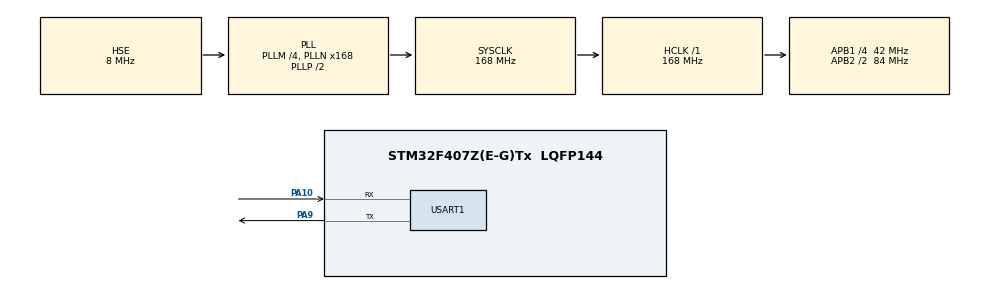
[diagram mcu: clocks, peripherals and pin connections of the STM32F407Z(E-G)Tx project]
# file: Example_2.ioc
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FREERTOS.Events01=xEventGroup,Dynamic,NULL
FREERTOS.Tasks01=Task_Syncing,24,128,AppTask_Syncing,Default,NULL,Dynamic,NULL,NULL
FREERTOS.configTICK_RATE_HZ=1000
FREERTOS.configUSE_IDLE_HOOK=0
Mcu.Family=STM32F4
Mcu.Name=STM32F407Z(E-G)Tx
Mcu.Package=LQFP144
NVIC.PriorityGroup=NVIC_PRIORITYGROUP_4
NVIC.TIM6_DAC_IRQn=true\:0\:0\:true\:false\:true\:false\:false\:true\:true
NVIC.TimeBase=TIM6_DAC_IRQn
NVIC.TimeBaseIP=TIM6
PA10.Mode=Asynchronous
PA10.Signal=USART1_RX
PA13.Mode=Serial_Wire
PA13.Signal=SYS_JTMS-SWDIO
PA14.Mode=Serial_Wire
PA14.Signal=SYS_JTCK-SWCLK
PA9.Mode=Asynchronous
PA9.Signal=USART1_TX
PC14-OSC32_IN.Mode=LSE-External-Oscillator
PC14-OSC32_IN.Signal=RCC_OSC32_IN
PC15-OSC32_OUT.Mode=LSE-External-Oscillator
PC15-OSC32_OUT.Signal=RCC_OSC32_OUT
PH0-OSC_IN.Mode=HSE-External-Oscillator
PH0-OSC_IN.Signal=RCC_OSC_IN
PH1-OSC_OUT.Mode=HSE-External-Oscillator
PH1-OSC_OUT.Signal=RCC_OSC_OUT
ProjectManager.HeapSize=0x200
ProjectManager.StackSize=0x400
ProjectManager.TargetToolchain=MDK-ARM V5.32
RCC.48MHZClocksFreq_Value=84000000
RCC.AHBFreq_Value=168000000
RCC.APB1CLKDivider=RCC_HCLK_DIV4
RCC.APB1Freq_Value=42000000
RCC.APB1TimFreq_Value=84000000
RCC.APB2CLKDivider=RCC_HCLK_DIV2
RCC.APB2Freq_Value=84000000
RCC.APB2TimFreq_Value=168000000
RCC.CortexFreq_Value=168000000
RCC.HCLKFreq_Value=168000000
RCC.HSE_VALUE=8000000
RCC.HSI_VALUE=16000000
RCC.PLLM=4
RCC.PLLN=168
RCC.PLLSourceVirtual=RCC_PLLSOURCE_HSE
RCC.RCC_RTC_Clock_Source=RCC_RTCCLKSOURCE_LSE
RCC.RCC_RTC_Clock_SourceVirtual=RCC_RTCCLKSOURCE_LSE
RCC.SYSCLKFreq_VALUE=168000000
RCC.SYSCLKSource=RCC_SYSCLKSOURCE_PLLCLK
RCC.VCOOutputFreq_Value=336000000
USART1.VirtualMode=VM_ASYNC
VP_FREERTOS_VS_CMSIS_V2.Mode=CMSIS_V2
VP_SYS_VS_tim6.Mode=TIM6
board=custom

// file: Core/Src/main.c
/* USER CODE BEGIN Header */
/**
  ******************************************************************************
  * @file           : main.c
  * @brief          : Main program body
  ******************************************************************************
  * @attention
  *
  * Copyright (c) 2024 STMicroelectronics.
  * All rights reserved.
  *
  * This software is licensed under terms that can be found in the LICENSE file
  * in the root directory of this software component.
  * If no LICENSE file comes with this software, it is provided AS-IS.
  *
  ******************************************************************************
  */
/* USER CODE END Header */
#include "main.h"
#include "cmsis_os.h"
#include "usart.h"
#include "gpio.h"

/* USER CODE BEGIN Includes */
#include "stdio.h"

#ifdef __GNUC__
#define PUTCHAR_PROTOTYPE int __io_putchar(int ch)
#else
#define PUTCHAR_PROTOTYPE int fputc(int ch, FILE *f)
#endif
PUTCHAR_PROTOTYPE
{
    HAL_UART_Transmit(&huart1, (uint8_t *)&ch, 1, HAL_MAX_DELAY);
    return ch;
}
/* USER CODE END Includes */

void SystemClock_Config(void);
void MX_FREERTOS_Init(void);

int main(void)
{

  /* MCU Configuration--------------------------------------------------------*/

  /* Reset of all peripherals, Initializes the Flash interface and the Systick. */
  HAL_Init();

  /* Configure the system clock */
  SystemClock_Config();

  /* Initialize all configured peripherals */
  MX_GPIO_Init();
  MX_USART1_UART_Init();

  /* Init scheduler */
  osKernelInitialize();

  /* Call init function for freertos objects (in freertos.c) */
  MX_FREERTOS_Init();

  /* Start scheduler */
  osKernelStart();

  /* We should never get here as control is now taken by the scheduler */
  /* Infinite loop */
  while (1)
  {

  }
}

void SystemClock_Config(void)
{
  RCC_OscInitTypeDef RCC_OscInitStruct = {0};
  RCC_ClkInitTypeDef RCC_ClkInitStruct = {0};

  /** Configure the main internal regulator output voltage
  */
  __HAL_RCC_PWR_CLK_ENABLE();
  __HAL_PWR_VOLTAGESCALING_CONFIG(PWR_REGULATOR_VOLTAGE_SCALE1);

  /** Initializes the RCC Oscillators according to the specified parameters
  * in the RCC_OscInitTypeDef structure.
  */
  RCC_OscInitStruct.OscillatorType = RCC_OSCILLATORTYPE_HSE;
  RCC_OscInitStruct.HSEState = RCC_HSE_ON;
  RCC_OscInitStruct.PLL.PLLState = RCC_PLL_ON;
  RCC_OscInitStruct.PLL.PLLSource = RCC_PLLSOURCE_HSE;
  RCC_OscInitStruct.PLL.PLLM = 4;
  RCC_OscInitStruct.PLL.PLLN = 168;
  RCC_OscInitStruct.PLL.PLLP = RCC_PLLP_DIV2;
  RCC_OscInitStruct.PLL.PLLQ = 4;
  if (HAL_RCC_OscConfig(&RCC_OscInitStruct) != HAL_OK)
  {
    Error_Handler();
  }

  /** Initializes the CPU, AHB and APB buses clocks
  */
  RCC_ClkInitStruct.ClockType = RCC_CLOCKTYPE_HCLK|RCC_CLOCKTYPE_SYSCLK
                              |RCC_CLOCKTYPE_PCLK1|RCC_CLOCKTYPE_PCLK2;
  RCC_ClkInitStruct.SYSCLKSource = RCC_SYSCLKSOURCE_PLLCLK;
  RCC_ClkInitStruct.AHBCLKDivider = RCC_SYSCLK_DIV1;
  RCC_ClkInitStruct.APB1CLKDivider = RCC_HCLK_DIV4;
  RCC_ClkInitStruct.APB2CLKDivider = RCC_HCLK_DIV2;

  if (HAL_RCC_ClockConfig(&RCC_ClkInitStruct, FLASH_LATENCY_5) != HAL_OK)
  {
    Error_Handler();
  }
}

void HAL_TIM_PeriodElapsedCallback(TIM_HandleTypeDef *htim)
{
  if (htim->Instance == TIM6) {
    HAL_IncTick();
  }
}

void Error_Handler(void)
{
  __disable_irq();
  while (1)
  {
  }
}

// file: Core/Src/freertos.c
/* USER CODE BEGIN Header */
/**
  ******************************************************************************
  * File Name          : freertos.c
  * Description        : Code for freertos applications
  ******************************************************************************
  * @attention
  *
  * Copyright (c) 2024 STMicroelectronics.
  * All rights reserved.
  *
  * This software is licensed under terms that can be found in the LICENSE file
  * in the root directory of this software component.
  * If no LICENSE file comes with this software, it is provided AS-IS.
  *
  ******************************************************************************
  */
/* USER CODE END Header */

#include "FreeRTOS.h"
#include "task.h"
#include "main.h"
#include "cmsis_os.h"

/* USER CODE BEGIN Includes */
#include "stdio.h"
#include "stdlib.h"
#include "event_groups.h"
/* USER CODE END Includes */

/* USER CODE BEGIN PM */
#define mainFIRST_TASK_BIT 	( 1UL << 0UL ) /* 事件组位 0 */
#define mainSECOND_TASK_BIT ( 1UL << 1UL ) /* 事件组位 1 */
#define mainTHIRD_TASK_BIT  ( 1UL << 2UL ) /* 事件组位 2 */
/* USER CODE END PM */

/* Definitions for Task_Syncing */
osThreadId_t Task_SyncingHandle;
const osThreadAttr_t Task_Syncing_attributes = {
  .name = "Task_Syncing",
  .stack_size = 128 * 4,
  .priority = (osPriority_t) osPriorityNormal,
};
/* Definitions for xEventGroup */
osEventFlagsId_t xEventGroupHandle;
const osEventFlagsAttr_t xEventGroup_attributes = {
  .name = "xEventGroup"
};

void AppTask_Syncing(void *argument);

void MX_FREERTOS_Init(void); /* (MISRA C 2004 rule 8.1) */

void MX_FREERTOS_Init(void) {

  /* Create the thread(s) */
  /* creation of Task_Syncing */
  //Task_SyncingHandle = osThreadNew(AppTask_Syncing, NULL, &Task_Syncing_attributes);

  /* USER CODE BEGIN RTOS_THREADS */
  /* add threads, ... */
	xTaskCreate(AppTask_Syncing, "Task 1", 1000, (void*)mainFIRST_TASK_BIT, osPriorityNormal, NULL );
	xTaskCreate(AppTask_Syncing, "Task 2", 1000, (void*)mainSECOND_TASK_BIT, osPriorityNormal, NULL );
	xTaskCreate(AppTask_Syncing, "Task 3", 1000, (void*)mainTHIRD_TASK_BIT, osPriorityNormal, NULL );
  /* USER CODE END RTOS_THREADS */

  /* Create the event(s) */
  /* creation of xEventGroup */
  xEventGroupHandle = osEventFlagsNew(&xEventGroup_attributes);

}

void AppTask_Syncing(void *argument)
{
  /* USER CODE BEGIN AppTask_Syncing */
	/* 创建两个延时用于合成随机延时时间 */
	const TickType_t xMaxDelay = pdMS_TO_TICKS(4000UL);
	const TickType_t xMinDelay = pdMS_TO_TICKS(200UL);
	/* 延时时间 */
	TickType_t xDelayTime;
	/* 任务要设置的事件组的位 */
	EventBits_t uxThisTasksSyncBit;
	/* 任务要等待的事件组的所有位 */
	const EventBits_t uxAllSyncBits = ( mainFIRST_TASK_BIT |
																			mainSECOND_TASK_BIT |
																			mainTHIRD_TASK_BIT );

	uxThisTasksSyncBit = ( EventBits_t )argument;
  /* Infinite loop */
  for(;;)
  {
		/* 合成随机延时时间，模拟三个任务不同时间到达同步点 */
		xDelayTime = (rand() % xMaxDelay) + xMinDelay;
		vTaskDelay(xDelayTime);
		printf("%s reached sync point\r\n", pcTaskGetTaskName(NULL));
		xEventGroupSync(/* 被读的事件组 */
										xEventGroupHandle,
										/* 测试的位 */
										uxThisTasksSyncBit,
										/* 需要等待的所有位 */
										uxAllSyncBits,
										/* 永远等待，不会超时 */
										portMAX_DELAY);
		/* 任务会同时退出同步点，串口输出需要时间，所以通过临界段保护串口输出 */
		taskENTER_CRITICAL();
		printf("%s exited sync point\r\n", pcTaskGetTaskName(NULL));
		taskEXIT_CRITICAL();
  }
  /* USER CODE END AppTask_Syncing */
}
